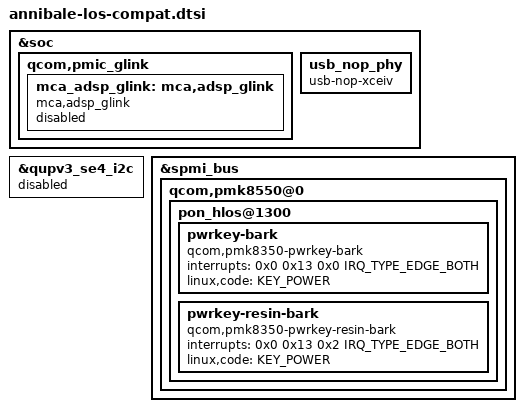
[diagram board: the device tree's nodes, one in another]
// SPDX-License-Identifier: BSD-3-Clause
/*
 * Copyright (c) Qualcomm Technologies, Inc. and/or its subsidiaries.
 * Copyright (c) 2022-2025 Qualcomm Innovation Center, Inc. All rights reserved.
 *
 * Annibale additions carried by MiCode's shared Sun DTS files.
 * Keep these board-specific additions out of the Qualcomm reference DTs.
 * Source: MiCode/kernel_devicetree annibale-w-oss,
 * commit 32fd4ddcedd46baa579643b3894c37c0fccccb91.
 */

&soc {
	/* The charging client belongs to the existing PMIC GLINK bus. */
	qcom,pmic_glink {
		mca_adsp_glink: mca,adsp_glink {
			compatible = "mca,adsp_glink";
			status = "disabled";
		};
	};

	/* Annibale wires DWC3 for high speed and uses this no-op SS PHY. */
	usb_nop_phy: usb_nop_phy {
		compatible = "usb-nop-xceiv";
	};
};

/* Keep the unused reference touchscreen bus disabled. */
&qupv3_se4_i2c {
	status = "disabled";
};

/* Paired with CONFIG_INPUT_PM8941_PWRKEY_XIAOMI in annibale_board.config. */
&spmi_bus {
	qcom,pmk8550@0 {
		pon_hlos@1300 {
			pwrkey-bark {
				compatible = "qcom,pmk8350-pwrkey-bark";
				interrupts = <0x0 0x13 0x0 IRQ_TYPE_EDGE_BOTH>;
				linux,code = <KEY_POWER>;
			};

			pwrkey-resin-bark {
				compatible = "qcom,pmk8350-pwrkey-resin-bark";
				interrupts = <0x0 0x13 0x2 IRQ_TYPE_EDGE_BOTH>;
				linux,code = <KEY_POWER>;
			};
		};
	};
};
